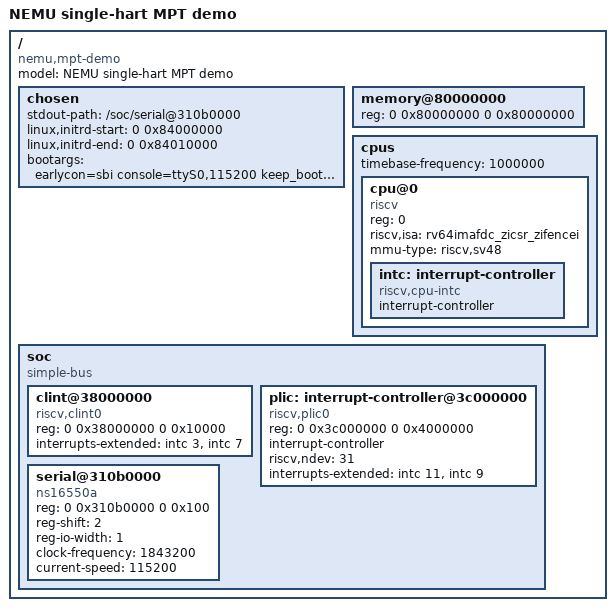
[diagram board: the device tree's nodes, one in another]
// SPDX-License-Identifier: BSD-2-Clause
/dts-v1/;
/ {
	#address-cells = <2>;
	#size-cells = <2>;
	compatible = "nemu,mpt-demo";
	model = "NEMU single-hart MPT demo";
	chosen {
		stdout-path = "/soc/serial@310b0000";
		linux,initrd-start = <0 0x84000000>;
		linux,initrd-end = <0 0x84010000>;
		bootargs = "earlycon=sbi console=ttyS0,115200 keep_bootcon loglevel=7 no4lvl";
	};
	memory@80000000 {
		device_type = "memory";
		reg = <0 0x80000000 0 0x80000000>;
	};
	cpus {
		#address-cells = <1>;
		#size-cells = <0>;
		timebase-frequency = <1000000>;
		cpu@0 {
			device_type = "cpu";
			reg = <0>;
			status = "okay";
			compatible = "riscv";
			riscv,isa = "rv64imafdc_zicsr_zifencei";
			mmu-type = "riscv,sv48";
			intc: interrupt-controller {
				#interrupt-cells = <1>;
				#address-cells = <0>;
				interrupt-controller;
				compatible = "riscv,cpu-intc";
			};
		};
	};
	soc {
		#address-cells = <2>;
		#size-cells = <2>;
		compatible = "simple-bus";
		ranges;
		clint@38000000 {
			compatible = "riscv,clint0";
			reg = <0 0x38000000 0 0x10000>;
			interrupts-extended = <&intc 3 &intc 7>;
		};
		plic: interrupt-controller@3c000000 {
			compatible = "riscv,plic0";
			reg = <0 0x3c000000 0 0x4000000>;
			#interrupt-cells = <1>;
			#address-cells = <0>;
			interrupt-controller;
			riscv,ndev = <31>;
			interrupts-extended = <&intc 11 &intc 9>;
		};
		serial@310b0000 {
			compatible = "ns16550a";
			reg = <0 0x310b0000 0 0x100>;
			reg-shift = <2>;
			reg-io-width = <1>;
			clock-frequency = <1843200>;
			current-speed = <115200>;
			/* NEMU's PLIC is a stub; use the 8250 polling fallback. */
		};
	};
};
